# S32M24x register map
Vendor: NXP Semiconductors; File version: 1.5
CPU: CM4 r0p1, little endian, MPU, FPU, VTOR, 4 interrupt priority bits
Registers are 32-bit, read-write, reset 0x0 unless marked. A register's access mark holds for its fields unless they carry their own. Offsets are from the block's base; [hi:lo] are bit positions; lines under a group give offsets from that group; {n}, {i} and the like mark numbered series.

## LPIT0 — LPIT
Base 0x40037000
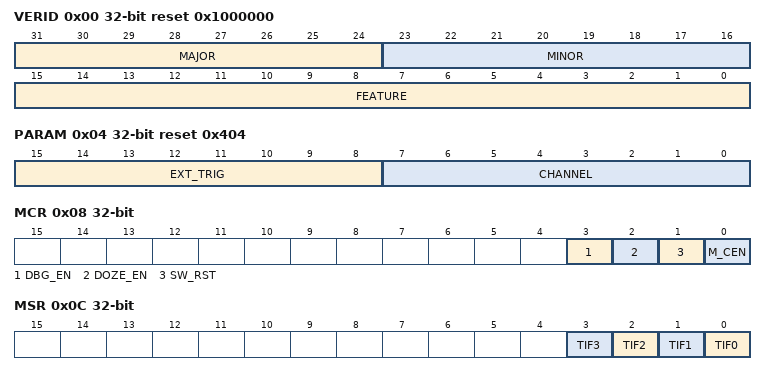
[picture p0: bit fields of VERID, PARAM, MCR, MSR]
0x00 VERID ro reset 0x1000000 — Version ID Register
  [31:24] MAJOR — Major Version Number
  [23:16] MINOR — Minor Version Number
  [15:0] FEATURE — Feature Number
0x04 PARAM ro reset 0x404 — Parameter Register
  [15:8] EXT_TRIG — Number of External Trigger Inputs
  [7:0] CHANNEL — Number of Timer Channels
0x08 MCR — Module Control Register
  [3] DBG_EN — Debug Enable Bit
    0=Stop timer channels in Debug mode; 1=Allow timer channels to continue to run in Debug mode
  [2] DOZE_EN — DOZE Mode Enable Bit
    0=Stop timer channels in DOZE mode; 1=Allow timer channels to continue to run in DOZE mode
  [1] SW_RST — Software Reset Bit
    0=Timer channels and registers are not reset; 1=Reset timer channels and registers
  [0] M_CEN — Module Clock Enable
    0=Disable peripheral clock to timers; 1=Enable peripheral clock to timers
0x0C MSR write-1-clears — Module Status Register
  [all] fields
    0=Timer has not timed out; 1=Timeout has occurred (timer has timed out)
  [n] TIF{n} write-1-clears (n=0..3) — Channel {n} Timer Interrupt Flag
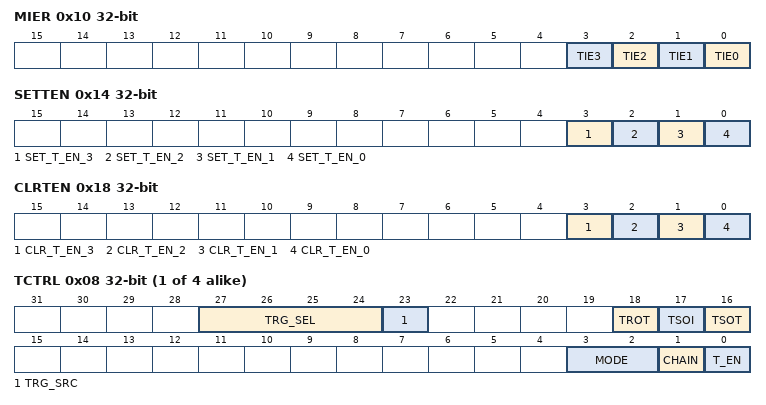
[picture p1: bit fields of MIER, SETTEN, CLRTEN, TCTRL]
0x10 MIER — Module Interrupt Enable Register
  [all] fields
    0=Disabled; 1=Enabled
  [n] TIE{n} (n=0..3) — Channel {n} Timer Interrupt Enable
0x14 SETTEN — Set Timer Enable Register
  [3] SET_T_EN_3 — Set Timer 3 Enable
    0=No effect; 1=Enables Timer Channel 3
  [2] SET_T_EN_2 — Set Timer 2 Enable
    0=No Effect; 1=Enables Timer Channel 2
  [1] SET_T_EN_1 — Set Timer 1 Enable
    0=No Effect; 1=Enables Timer Channel 1
  [0] SET_T_EN_0 — Set Timer 0 Enable
    0=No effect; 1=Enables Timer Channel 0
0x18 CLRTEN — Clear Timer Enable Register
  [3] CLR_T_EN_3 — Clear Timer 3 Enable
    0=No Action; 1=Clear the Timer Enable bit (TCTRL3[T_EN]) for Timer Channel 3
  [2] CLR_T_EN_2 — Clear Timer 2 Enable
    0=No Action; 1=Clear the Timer Enable bit (TCTRL2[T_EN]) for Timer Channel 2
  [1] CLR_T_EN_1 — Clear Timer 1 Enable
    0=No Action; 1=Clear the Timer Enable bit (TCTRL1[T_EN]) for Timer Channel 1
  [0] CLR_T_EN_0 — Clear Timer 0 Enable
    0=No action; 1=Clear the Timer Enable bit (TCTRL0[T_EN]) for Timer Channel 0
{0x20+0x10*i} CHANNEL[{i}] (i=0..3) group — Array of registers: TVAL, CVAL, TCTRL
  0x00 TVAL — Timer Value Register
    [31:0] TMR_VAL — Timer Value
      0=Invalid load value in compare mode; 1=Invalid load value in compare mode; {v}=In compare mode: the value to be loaded; in capture mode, the value of the timer (v=2..9)
  0x04 CVAL ro reset 0xFFFFFFFF — Current Timer Value
    [31:0] TMR_CUR_VAL
  0x08 TCTRL — Timer Control Register
    [27:24] TRG_SEL — Trigger Select
      {v}=Timer channel 0 - 3 trigger source is selected (v=0..3)
    [23] TRG_SRC — Trigger Source
      0=Selects external triggers; 1=Selects internal triggers
    [18] TROT — Timer Reload On Trigger
      0=Timer will not reload on the selected trigger; 1=Timer will reload on the selected trigger
    [17] TSOI — Timer Stop On Interrupt
      0=The channel timer does not stop after timeout; 1=The channel timer will stop after a timeout, and the channel timer will restart based on Timer Start On Trigger bit (TSOT). When TSOT = 0, the channel timer will restart after a rising edge on the Timer Enable bit (T_EN) is detected (which means that the timer channel is disabled and then enabled). When TSOT = 1, the channel timer will restart after a rising edge on the selected trigger is detected.
    [16] TSOT — Timer Start On Trigger
      0=Timer starts to decrement immediately based on the restart condition (controlled by the Timer Stop On Interrupt bit (TSOI)); 1=Timer starts to decrement when a rising edge on a selected trigger is detected
    [3:2] MODE — Timer Operation Mode
      0=32-bit Periodic Counter; 1=Dual 16-bit Periodic Counter; 2=32-bit Trigger Accumulator; 3=32-bit Trigger Input Capture
    [1] CHAIN — Chain Channel
      0=Channel Chaining is disabled. The channel timer runs independently.; 1=Channel Chaining is enabled. The timer decrements on the previous channel's timeout.
    [0] T_EN — Timer Enable
      0=Timer Channel is disabled; 1=Timer Channel is enabled
